# nrf9120 register map
Vendor: Nordic Semiconductor; Series: nrf91; File version: 1
CPU: CM33 r0p4, little endian, MPU, FPU, 3 interrupt priority bits, 69 interrupts
Registers are 32-bit, read-write, reset 0x0 unless marked. A register's access mark holds for its fields unless they carry their own. Offsets are from the block's base; [hi:lo] are bit positions; 'fields as' and 'values as' point back to an identical list.

## CLOCK_NS — Clock management 0
Base 0x40005000
Same registers: CLOCK_S 0x50005000
0x00 TASKS_HFCLKSTART wo — Start HFCLK source
  [0] TASKS_HFCLKSTART
    1=Trigger task
0x04 TASKS_HFCLKSTOP wo — Stop HFCLK source
  [0] TASKS_HFCLKSTOP
    1=Trigger task
0x08 TASKS_LFCLKSTART wo — Start LFCLK source
  [0] TASKS_LFCLKSTART
    1=Trigger task
0x0C TASKS_LFCLKSTOP wo — Stop LFCLK source
  [0] TASKS_LFCLKSTOP
    1=Trigger task
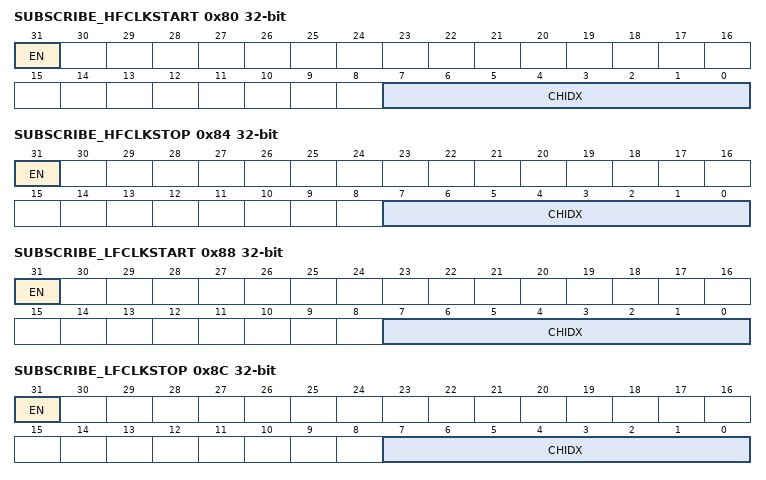
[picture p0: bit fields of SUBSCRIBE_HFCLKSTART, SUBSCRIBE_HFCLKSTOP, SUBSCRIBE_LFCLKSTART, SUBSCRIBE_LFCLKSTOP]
0x80 SUBSCRIBE_HFCLKSTART — Subscribe configuration for task HFCLKSTART
  [31] EN
    0=Disabled (Disable subscription); 1=Enabled (Enable subscription)
  [7:0] CHIDX — DPPI channel that task HFCLKSTART will subscribe to
0x84 SUBSCRIBE_HFCLKSTOP — Subscribe configuration for task HFCLKSTOP
  [31] EN
    values as SUBSCRIBE_HFCLKSTART.EN
  [7:0] CHIDX — DPPI channel that task HFCLKSTOP will subscribe to
0x88 SUBSCRIBE_LFCLKSTART — Subscribe configuration for task LFCLKSTART
  [31] EN
    values as SUBSCRIBE_HFCLKSTART.EN
  [7:0] CHIDX — DPPI channel that task LFCLKSTART will subscribe to
0x8C SUBSCRIBE_LFCLKSTOP — Subscribe configuration for task LFCLKSTOP
  [31] EN
    values as SUBSCRIBE_HFCLKSTART.EN
  [7:0] CHIDX — DPPI channel that task LFCLKSTOP will subscribe to
0x100 EVENTS_HFCLKSTARTED — HFCLK oscillator started
  [0] EVENTS_HFCLKSTARTED
    0=NotGenerated (Event not generated); 1=Generated (Event generated)
0x104 EVENTS_LFCLKSTARTED — LFCLK started
  [0] EVENTS_LFCLKSTARTED
    values as EVENTS_HFCLKSTARTED.EVENTS_HFCLKSTARTED
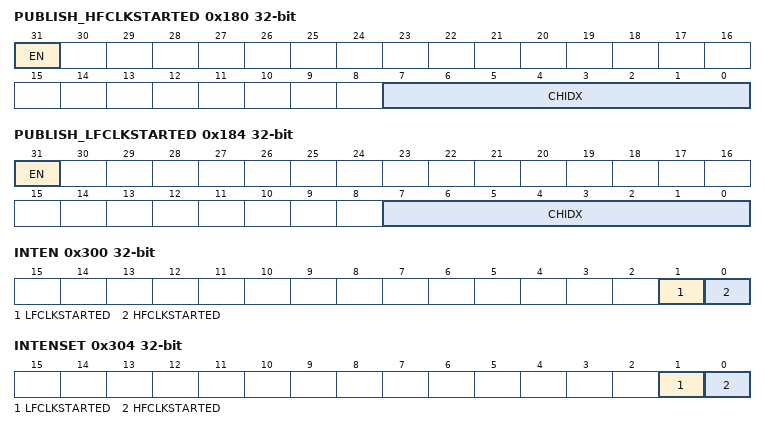
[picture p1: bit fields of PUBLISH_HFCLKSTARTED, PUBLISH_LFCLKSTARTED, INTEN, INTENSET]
0x180 PUBLISH_HFCLKSTARTED — Publish configuration for event HFCLKSTARTED
  [31] EN
    0=Disabled (Disable publishing); 1=Enabled (Enable publishing)
  [7:0] CHIDX — DPPI channel that event HFCLKSTARTED will publish to
0x184 PUBLISH_LFCLKSTARTED — Publish configuration for event LFCLKSTARTED
  [31] EN
    values as PUBLISH_HFCLKSTARTED.EN
  [7:0] CHIDX — DPPI channel that event LFCLKSTARTED will publish to
0x300 INTEN — Enable or disable interrupt
  [1] LFCLKSTARTED — Enable or disable interrupt for event LFCLKSTARTED
    0=Disabled; 1=Enabled
  [0] HFCLKSTARTED — Enable or disable interrupt for event HFCLKSTARTED
    0=Disabled; 1=Enabled
0x304 INTENSET — Enable interrupt
  [1] LFCLKSTARTED — Write '1' to enable interrupt for event LFCLKSTARTED
    on read: 0=Disabled (Read: Disabled); 1=Enabled (Read: Enabled) | on write: 1=Set (Enable)
  [0] HFCLKSTARTED — Write '1' to enable interrupt for event HFCLKSTARTED
    values as LFCLKSTARTED
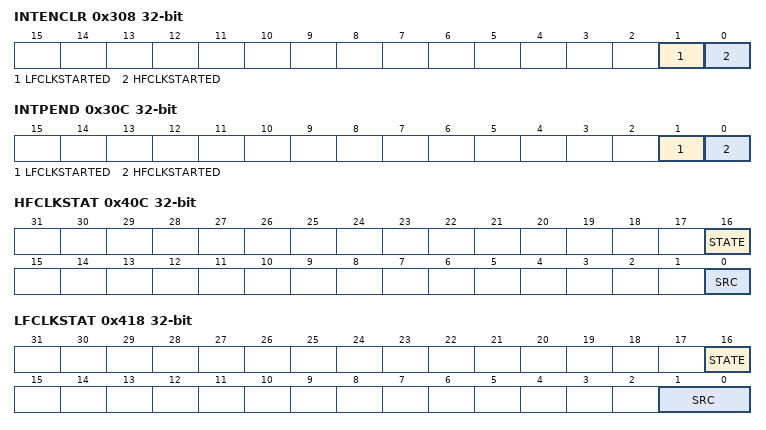
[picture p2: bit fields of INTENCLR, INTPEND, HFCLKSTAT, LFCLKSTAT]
0x308 INTENCLR — Disable interrupt
  [1] LFCLKSTARTED — Write '1' to disable interrupt for event LFCLKSTARTED
    on read: 0=Disabled (Read: Disabled); 1=Enabled (Read: Enabled) | on write: 1=Clear (Disable)
  [0] HFCLKSTARTED — Write '1' to disable interrupt for event HFCLKSTARTED
    values as LFCLKSTARTED
0x30C INTPEND ro — Pending interrupts
  [1] LFCLKSTARTED — Read pending status of interrupt for event LFCLKSTARTED
    on read: 0=NotPending (Read: Not pending); 1=Pending (Read: Pending)
  [0] HFCLKSTARTED — Read pending status of interrupt for event HFCLKSTARTED
    values as LFCLKSTARTED
0x408 HFCLKRUN ro — Status indicating that HFCLKSTART task has been triggered
  [0] STATUS — HFCLKSTART task triggered or not
    0=NotTriggered (Task not triggered); 1=Triggered (Task triggered)
0x40C HFCLKSTAT ro — The register shows if HFXO has been requested by triggering HFCLKSTART task and if it has been started (STATE)
  [16] STATE — HFCLK state
    0=NotRunning (HFXO has not been started or HFCLKSTOP task has been triggered); 1=Running (HFXO has been started (HFCLKSTARTED event has been generated))
  [0] SRC — Active clock source
    0=HFINT (HFINT - 64 MHz on-chip oscillator); 1=HFXO (HFXO - 64 MHz clock derived from external 32 MHz crystal oscillator)
0x414 LFCLKRUN ro — Status indicating that LFCLKSTART task has been triggered
  [0] STATUS — LFCLKSTART task triggered or not
    values as HFCLKRUN.STATUS
0x418 LFCLKSTAT ro — The register shows which LFCLK source has been requested (SRC) when triggering LFCLKSTART task and if the source has been started (STATE)
  [16] STATE — LFCLK state
    0=NotRunning (Requested LFCLK source has not been started or LFCLKSTOP task has been triggered); 1=Running (Requested LFCLK source has been started (LFCLKSTARTED event has been generated))
  [1:0] SRC — Active clock source
    1=LFRC (32.768 kHz RC oscillator); 2=LFXO (32.768 kHz crystal oscillator)
0x41C LFCLKSRCCOPY ro reset 0x1 — Copy of LFCLKSRC register, set after LFCLKSTART task has been triggered
  [1:0] SRC — Clock source
    values as LFCLKSTAT.SRC
0x518 LFCLKSRC reset 0x1 — Clock source for the LFCLK. LFCLKSTART task starts starts a clock source selected with this register.
  fields as LFCLKSRCCOPY

## Notices in the file
Copyright (c) 2010 - 2023, Nordic Semiconductor ASA
All rights reserved.
Redistribution and use in source and binary forms, with or without modification,
are permitted provided that the following conditions are met:
1. Redistributions of source code must retain the above copyright notice, this
list of conditions and the following disclaimer.
2. Redistributions in binary form, except as embedded into a Nordic
Semiconductor ASA integrated circuit in a product or a software update for
such product, must reproduce the above copyright notice, this list of
conditions and the following disclaimer in the documentation and/or other
materials provided with the distribution.
3. Neither the name of Nordic Semiconductor ASA nor the names of its
contributors may be used to endorse or promote products derived from this
software without specific prior written permission.
4. This software, with or without modification, must only be used with a
Nordic Semiconductor ASA integrated circuit.
5. Any software provided in binary form under this license must not be reverse
engineered, decompiled, modified and/or disassembled.
THIS SOFTWARE IS PROVIDED BY NORDIC SEMICONDUCTOR ASA "AS IS" AND ANY EXPRESS
OR IMPLIED WARRANTIES, INCLUDING, BUT NOT LIMITED TO, THE IMPLIED WARRANTIES
OF MERCHANTABILITY, NONINFRINGEMENT, AND FITNESS FOR A PARTICULAR PURPOSE ARE
DISCLAIMED. IN NO EVENT SHALL NORDIC SEMICONDUCTOR ASA OR CONTRIBUTORS BE
LIABLE FOR ANY DIRECT, INDIRECT, INCIDENTAL, SPECIAL, EXEMPLARY, OR
CONSEQUENTIAL DAMAGES (INCLUDING, BUT NOT LIMITED TO, PROCUREMENT OF SUBSTITUTE
GOODS OR SERVICES; LOSS OF USE, DATA, OR PROFITS; OR BUSINESS INTERRUPTION)
HOWEVER CAUSED AND ON ANY THEORY OF LIABILITY, WHETHER IN CONTRACT, STRICT
LIABILITY, OR TORT (INCLUDING NEGLIGENCE OR OTHERWISE) ARISING IN ANY WAY OUT
OF THE USE OF THIS SOFTWARE, EVEN IF ADVISED OF THE POSSIBILITY OF SUCH DAMAGE.
